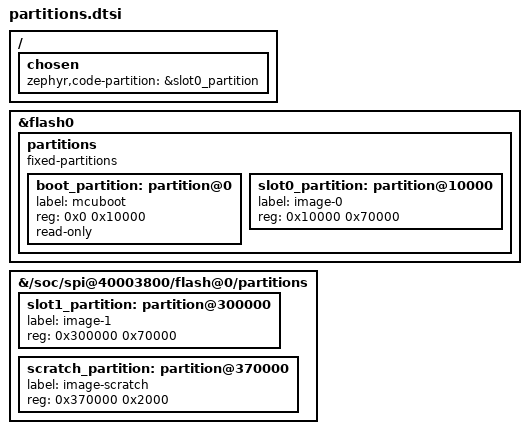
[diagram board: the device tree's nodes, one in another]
/* 当前 MCUboot 镜像布局。 */
/ {
    chosen { zephyr,code-partition = &slot0_partition; };
};
&flash0 {
    partitions {
        compatible = "fixed-partitions";
        #address-cells = <1>;
        #size-cells = <1>;
        boot_partition: partition@0 {
            label = "mcuboot";
            reg = <0x0 0x10000>;
            read-only;
        };
        slot0_partition: partition@10000 {
            label = "image-0";
            reg = <0x10000 0x70000>;
        };
    };
};
/* 外部镜像槽和交换暂存区；参数与 IAP 地址保持固定。 */
&{/soc/spi@40003800/flash@0/partitions} {
    slot1_partition: partition@300000 {
        label = "image-1";
        reg = <0x300000 0x70000>;
    };
    scratch_partition: partition@370000 {
        label = "image-scratch";
        reg = <0x370000 0x2000>;
    };
};
